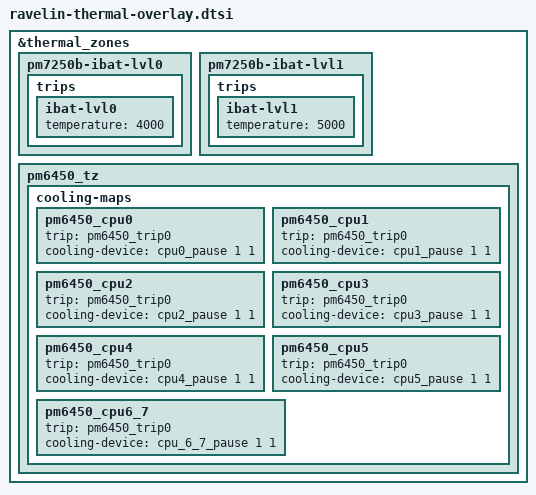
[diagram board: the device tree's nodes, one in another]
#include <dt-bindings/thermal/thermal_qti.h>

&thermal_zones {
	pm7250b-ibat-lvl0 {
		trips {
			ibat-lvl0 {
				temperature = <4000>;
			};
		};
	};

	pm7250b-ibat-lvl1 {
		trips {
			ibat-lvl1 {
				temperature = <5000>;
			};
		};
	};

	pm6450_tz {
		cooling-maps {
			pm6450_cpu0 {
				trip = <&pm6450_trip0>;
				cooling-device = <&cpu0_pause 1 1>;
			};

			pm6450_cpu1 {
				trip = <&pm6450_trip0>;
				cooling-device = <&cpu1_pause 1 1>;
			};

			pm6450_cpu2 {
				trip = <&pm6450_trip0>;
				cooling-device = <&cpu2_pause 1 1>;
			};

			pm6450_cpu3 {
				trip = <&pm6450_trip0>;
				cooling-device = <&cpu3_pause 1 1>;
			};

			pm6450_cpu4 {
				trip = <&pm6450_trip0>;
				cooling-device = <&cpu4_pause 1 1>;
			};

			pm6450_cpu5 {
				trip = <&pm6450_trip0>;
				cooling-device = <&cpu5_pause 1 1>;
			};

			pm6450_cpu6_7 {
				trip = <&pm6450_trip0>;
				cooling-device = <&cpu_6_7_pause 1 1>;
			};
		};
	};
};
